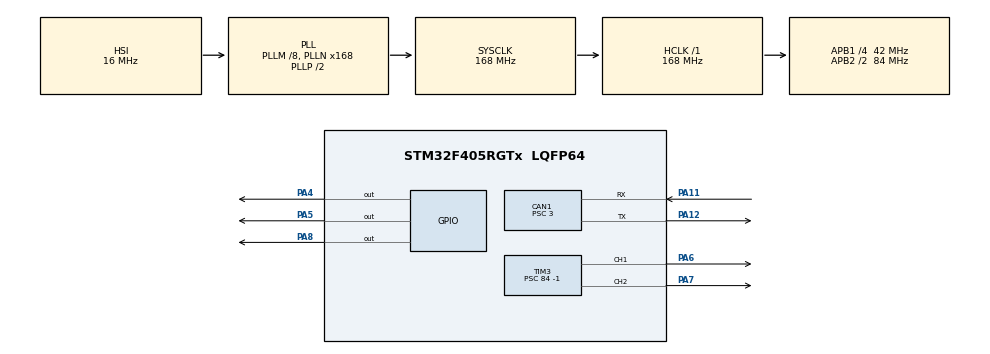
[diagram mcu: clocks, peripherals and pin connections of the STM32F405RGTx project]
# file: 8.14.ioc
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CAN1.ABOM=ENABLE
CAN1.AWUM=ENABLE
CAN1.BS1=CAN_BS1_9TQ
CAN1.BS2=CAN_BS2_4TQ
CAN1.CalculateBaudRate=1000000
CAN1.CalculateTimeBit=1000
CAN1.CalculateTimeQuantum=71.42857142857143
CAN1.NART=ENABLE
CAN1.Prescaler=3
FREERTOS.Tasks01=LEDTask,24,128,Led_Task,As weak,NULL,Dynamic,NULL,NULL;BuzzerTask,8,128,Beep_Task,As weak,NULL,Static,BuzzerTaskBuffer,BuzzerTaskControlBlock
Mcu.Family=STM32F4
Mcu.Name=STM32F405RGTx
Mcu.Package=LQFP64
NVIC.CAN1_RX0_IRQn=true\:5\:0\:false\:false\:true\:true\:true\:true\:true
NVIC.CAN1_RX1_IRQn=true\:5\:0\:false\:false\:true\:true\:true\:true\:true
NVIC.PriorityGroup=NVIC_PRIORITYGROUP_4
NVIC.TIM1_UP_TIM10_IRQn=true\:15\:0\:false\:false\:true\:false\:false\:true\:true
NVIC.TimeBase=TIM1_UP_TIM10_IRQn
NVIC.TimeBaseIP=TIM1
PA11.Mode=CAN_Activate
PA11.Signal=CAN1_RX
PA12.Mode=CAN_Activate
PA12.Signal=CAN1_TX
PA13.Mode=Serial_Wire
PA13.Signal=SYS_JTMS-SWDIO
PA14.Mode=Serial_Wire
PA14.Signal=SYS_JTCK-SWCLK
PA4.Signal=GPIO_Output
PA5.Signal=GPIO_Output
PA6.Signal=S_TIM3_CH1
PA7.Signal=S_TIM3_CH2
PA8.Signal=GPIO_Output
ProjectManager.HeapSize=0x200
ProjectManager.StackSize=0x400
ProjectManager.TargetToolchain=MDK-ARM V5.32
RCC.48MHZClocksFreq_Value=84000000
RCC.AHBFreq_Value=168000000
RCC.APB1CLKDivider=RCC_HCLK_DIV4
RCC.APB1Freq_Value=42000000
RCC.APB1TimFreq_Value=84000000
RCC.APB2CLKDivider=RCC_HCLK_DIV2
RCC.APB2Freq_Value=84000000
RCC.APB2TimFreq_Value=168000000
RCC.CortexFreq_Value=168000000
RCC.HCLKFreq_Value=168000000
RCC.HSE_VALUE=25000000
RCC.HSI_VALUE=16000000
RCC.LSE_VALUE=32768
RCC.PLLM=8
RCC.PLLN=168
RCC.SYSCLKFreq_VALUE=168000000
RCC.SYSCLKSource=RCC_SYSCLKSOURCE_PLLCLK
RCC.VCOOutputFreq_Value=336000000
SH.S_TIM3_CH1.0=TIM3_CH1,PWM Generation1 CH1
SH.S_TIM3_CH2.0=TIM3_CH2,PWM Generation2 CH2
TIM3.AutoReloadPreload=TIM_AUTORELOAD_PRELOAD_ENABLE
TIM3.Channel-PWM\ Generation1\ CH1=TIM_CHANNEL_1
TIM3.Channel-PWM\ Generation2\ CH2=TIM_CHANNEL_2
TIM3.Period=1000 - 1
TIM3.Prescaler=84 -1
VP_FREERTOS_VS_CMSIS_V2.Mode=CMSIS_V2
VP_SYS_VS_tim1.Mode=TIM1
VP_TIM3_VS_ClockSourceINT.Mode=Internal
board=custom

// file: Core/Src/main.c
/* USER CODE BEGIN Header */
/**
  ******************************************************************************
  * @file           : main.c
  * @brief          : Main program body
  ******************************************************************************
  * @attention
  *
  * Copyright (c) 2026 STMicroelectronics.
  * All rights reserved.
  *
  * This software is licensed under terms that can be found in the LICENSE file
  * in the root directory of this software component.
  * If no LICENSE file comes with this software, it is provided AS-IS.
  *
  ******************************************************************************
  */
/* USER CODE END Header */
#include "main.h"
#include "cmsis_os.h"
#include "can.h"
#include "tim.h"
#include "gpio.h"

/* USER CODE BEGIN Includes */
#include "breathing_led.h"
#include "CAN_IRQ_Handler.h"
/* USER CODE END Includes */

void SystemClock_Config(void);
void MX_FREERTOS_Init(void);

int main(void)
{

  /* MCU Configuration--------------------------------------------------------*/

  /* Reset of all peripherals, Initializes the Flash interface and the Systick. */
  HAL_Init();

  /* Configure the system clock */
  SystemClock_Config();

  /* Initialize all configured peripherals */
  MX_GPIO_Init();
  MX_TIM3_Init();
  MX_CAN1_Init();
  /* USER CODE BEGIN 2 */
  HAL_TIM_PWM_Start(&htim3, TIM_CHANNEL_1);
  HAL_TIM_PWM_Start(&htim3, TIM_CHANNEL_1);
  HAL_CAN_Start(&hcan1);
  HAL_CAN_ActivateNotification(&hcan1, CAN_IT_RX_FIFO0_MSG_PENDING);
  breathing_led();
  /* USER CODE END 2 */

  /* Init scheduler */
  osKernelInitialize();  /* Call init function for freertos objects (in cmsis_os2.c) */
  MX_FREERTOS_Init();

  /* Start scheduler */
  osKernelStart();

  /* We should never get here as control is now taken by the scheduler */

  /* Infinite loop */
  while (1)
  {

  }
}

void SystemClock_Config(void)
{
  RCC_OscInitTypeDef RCC_OscInitStruct = {0};
  RCC_ClkInitTypeDef RCC_ClkInitStruct = {0};

  /** Configure the main internal regulator output voltage
  */
  __HAL_RCC_PWR_CLK_ENABLE();
  __HAL_PWR_VOLTAGESCALING_CONFIG(PWR_REGULATOR_VOLTAGE_SCALE1);

  /** Initializes the RCC Oscillators according to the specified parameters
  * in the RCC_OscInitTypeDef structure.
  */
  RCC_OscInitStruct.OscillatorType = RCC_OSCILLATORTYPE_HSI;
  RCC_OscInitStruct.HSIState = RCC_HSI_ON;
  RCC_OscInitStruct.HSICalibrationValue = RCC_HSICALIBRATION_DEFAULT;
  RCC_OscInitStruct.PLL.PLLState = RCC_PLL_ON;
  RCC_OscInitStruct.PLL.PLLSource = RCC_PLLSOURCE_HSI;
  RCC_OscInitStruct.PLL.PLLM = 8;
  RCC_OscInitStruct.PLL.PLLN = 168;
  RCC_OscInitStruct.PLL.PLLP = RCC_PLLP_DIV2;
  RCC_OscInitStruct.PLL.PLLQ = 4;
  if (HAL_RCC_OscConfig(&RCC_OscInitStruct) != HAL_OK)
  {
    Error_Handler();
  }

  /** Initializes the CPU, AHB and APB buses clocks
  */
  RCC_ClkInitStruct.ClockType = RCC_CLOCKTYPE_HCLK|RCC_CLOCKTYPE_SYSCLK
                              |RCC_CLOCKTYPE_PCLK1|RCC_CLOCKTYPE_PCLK2;
  RCC_ClkInitStruct.SYSCLKSource = RCC_SYSCLKSOURCE_PLLCLK;
  RCC_ClkInitStruct.AHBCLKDivider = RCC_SYSCLK_DIV1;
  RCC_ClkInitStruct.APB1CLKDivider = RCC_HCLK_DIV4;
  RCC_ClkInitStruct.APB2CLKDivider = RCC_HCLK_DIV2;

  if (HAL_RCC_ClockConfig(&RCC_ClkInitStruct, FLASH_LATENCY_5) != HAL_OK)
  {
    Error_Handler();
  }
}

void HAL_TIM_PeriodElapsedCallback(TIM_HandleTypeDef *htim)
{
  if (htim->Instance == TIM1)
  {
    HAL_IncTick();
  }
}

void Error_Handler(void)
{
  __disable_irq();
  while (1)
  {
  }
}
